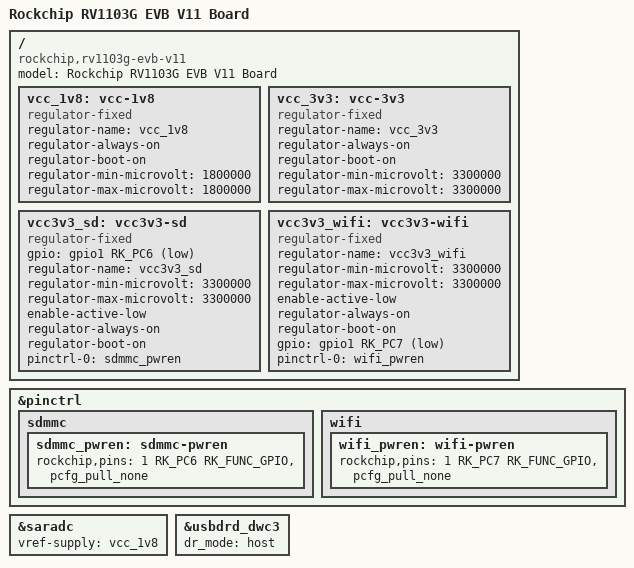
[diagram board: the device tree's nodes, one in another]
// SPDX-License-Identifier: (GPL-2.0+ OR MIT)
/*
 * Copyright (c) 2022 Rockchip Electronics Co., Ltd.
 */

/dts-v1/;

#include "rv1103.dtsi"
#include "rv1103-evb-v10.dtsi"
#include "rv1103-evb-cam.dtsi"

/ {
	model = "Rockchip RV1103G EVB V11 Board";
	compatible = "rockchip,rv1103g-evb-v11", "rockchip,rv1103";

	vcc_1v8: vcc-1v8 {
		compatible = "regulator-fixed";
		regulator-name = "vcc_1v8";
		regulator-always-on;
		regulator-boot-on;
		regulator-min-microvolt = <1800000>;
		regulator-max-microvolt = <1800000>;
	};

	vcc_3v3: vcc-3v3 {
		compatible = "regulator-fixed";
		regulator-name = "vcc_3v3";
		regulator-always-on;
		regulator-boot-on;
		regulator-min-microvolt = <3300000>;
		regulator-max-microvolt = <3300000>;
	};

	vcc3v3_sd: vcc3v3-sd {
		compatible = "regulator-fixed";
		gpio = <&gpio1 RK_PC6 GPIO_ACTIVE_LOW>;
		regulator-name = "vcc3v3_sd";
		regulator-min-microvolt = <3300000>;
		regulator-max-microvolt = <3300000>;
		enable-active-low;
		regulator-always-on;
		regulator-boot-on;
		pinctrl-names = "default";
		pinctrl-0 = <&sdmmc_pwren>;
	};

	vcc3v3_wifi: vcc3v3-wifi {
		compatible = "regulator-fixed";
		regulator-name = "vcc3v3_wifi";
		regulator-min-microvolt = <3300000>;
		regulator-max-microvolt = <3300000>;
		enable-active-low;
		regulator-always-on;
		regulator-boot-on;
		gpio = <&gpio1 RK_PC7 GPIO_ACTIVE_LOW>;
		pinctrl-names = "default";
		pinctrl-0 = <&wifi_pwren>;
	};
};

&pinctrl {
	sdmmc {
		/omit-if-no-ref/
		sdmmc_pwren: sdmmc-pwren {
			rockchip,pins = <1 RK_PC6 RK_FUNC_GPIO &pcfg_pull_none>;
		};
	};

	wifi {
		wifi_pwren: wifi-pwren {
			rockchip,pins = <1 RK_PC7 RK_FUNC_GPIO &pcfg_pull_none>;
		};
	};
};

&saradc {
	status = "okay";
	vref-supply = <&vcc_1v8>;
};

&usbdrd_dwc3 {
	dr_mode = "host";
};
